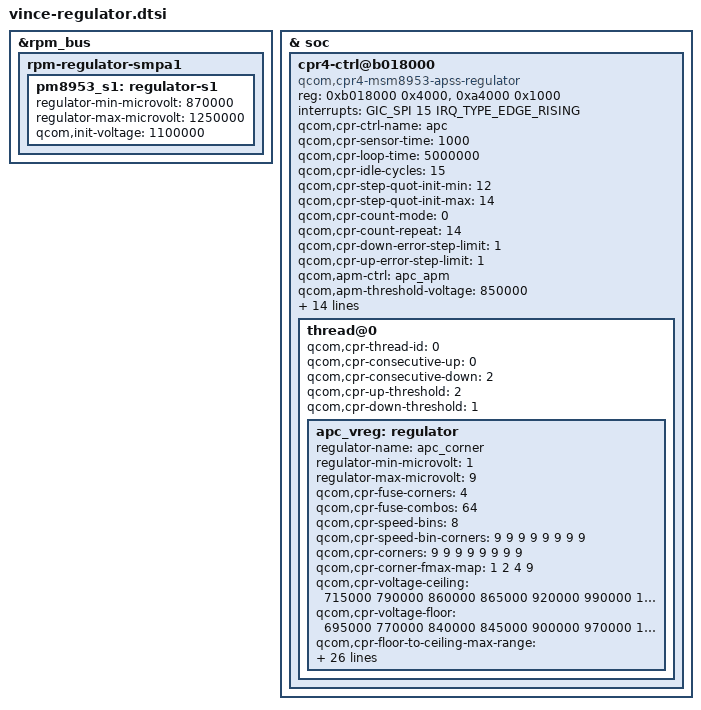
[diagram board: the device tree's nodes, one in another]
/*
 * Copyright (c) 2015-2016, 2019, The Linux Foundation. All rights reserved.
 *
 * This program is free software; you can redistribute it and/or modify
 * it under the terms of the GNU General Public License version 2 and
 * only version 2 as published by the Free Software Foundation.
 *
 * This program is distributed in the hope that it will be useful,
 * but WITHOUT ANY WARRANTY; without even the implied warranty of
 * MERCHANTABILITY or FITNESS FOR A PARTICULAR PURPOSE.  See the
 * GNU General Public License for more details.
 */

&rpm_bus {
	/delete-node/ rpm-regulator-smpa1;

	rpm-regulator-smpa1 {
		status = "okay";
		pm8953_s1: regulator-s1 {
			regulator-min-microvolt =
					<870000>;
			regulator-max-microvolt =
					<1250000>;
			qcom,init-voltage = <1100000>;
			status = "okay";
		};
	};
};

& soc {
	/delete-node/ cpr4-ctrl@b018000;

	cpr4-ctrl@b018000 {
		compatible = "qcom,cpr4-msm8953-apss-regulator";
		reg = <0xb018000 0x4000>, <0xa4000 0x1000>;
		reg-names = "cpr_ctrl", "fuse_base";
		interrupts = <GIC_SPI 15 IRQ_TYPE_EDGE_RISING>;
		interrupt-names = "cpr";

		qcom,cpr-ctrl-name = "apc";

		qcom,cpr-sensor-time = <1000>;
		qcom,cpr-loop-time = <5000000>;
		qcom,cpr-idle-cycles = <15>;
		qcom,cpr-step-quot-init-min = <12>;
		qcom,cpr-step-quot-init-max = <14>;
		qcom,cpr-count-mode = <0>;		/* All-at-once */
		qcom,cpr-count-repeat = <14>;
		qcom,cpr-down-error-step-limit = <1>;
		qcom,cpr-up-error-step-limit = <1>;

		qcom,apm-ctrl = <&apc_apm>;
		qcom,apm-threshold-voltage = <850000>;
		qcom,apm-hysteresis-voltage = <5000>;

		vdd-supply = <&pm8953_s5>;
		qcom,voltage-step = <5000>;
		vdd-limit-supply = <&pm8953_s5_limit>;
		mem-acc-supply = <&apc_mem_acc_vreg>;

		qcom,cpr-enable;
		qcom,cpr-hw-closed-loop;

		qcom,cpr-panic-reg-addr-list =
			<0xb1d2c18 0xb1d2900 0x0b1112b0 0xb018798>;
		qcom,cpr-panic-reg-name-list =
			"CCI_SAW4_PMIC_STS", "CCI_SAW4_VCTL",
			"APCS_ALIAS0_APM_CTLER_STATUS",
			"APCS0_CPR_CORE_ADJ_MODE_REG";

		/* Turbo (corner 6) ceiling voltage */
		qcom,cpr-aging-ref-voltage = <990000>;

		thread@0 {
			qcom,cpr-thread-id = <0>;
			qcom,cpr-consecutive-up = <0>;
			qcom,cpr-consecutive-down = <2>;
			qcom,cpr-up-threshold = <2>;
			qcom,cpr-down-threshold = <1>;

			apc_vreg: regulator {
				regulator-name = "apc_corner";
				regulator-min-microvolt = <1>;
				regulator-max-microvolt = <9>;

				qcom,cpr-fuse-corners = <4>;
				qcom,cpr-fuse-combos = <64>;
				qcom,cpr-speed-bins = <8>;
				qcom,cpr-speed-bin-corners =
					<9 9 9 9 9 9 9 9>;
				qcom,cpr-corners =
					<9 9 9 9 9 9 9 9>;

				qcom,cpr-corner-fmax-map =
					<1 2 4 9>;

				qcom,cpr-voltage-ceiling =
					<715000 790000 860000 865000 920000
					 990000 1065000 1095000 1100000>;

				qcom,cpr-voltage-floor =
					<695000 770000 840000 845000 900000
					 970000 1045000 1075000 1080000>;

				qcom,cpr-floor-to-ceiling-max-range =
					 <50000 50000 50000 50000 50000
					  50000 50000 50000 50000>;

				qcom,mem-acc-voltage =
					<1 1 2 2 2 2 2 2 2>;

				qcom,corner-frequencies =
					<652800000 1036800000 1401600000
					1689600000 1804800000 1958400000
					2016000000 2150400000 2208000000>;

				qcom,cpr-open-loop-voltage-fuse-adjustment =
					<     0      0      0     0>,
					< 25000      0   5000 40000>,
					< 25000      0   5000 40000>,
					< 25000      0   5000 40000>,
					<     0      0      0     0>,
					<     0      0      0     0>,
					<     0      0      0     0>,
					<     0      0      0     0>;

				qcom,cpr-closed-loop-voltage-fuse-adjustment =
					<      0        0        0      0>,
					<  10000 (-15000)        0  25000>,
					<  10000 (-15000)        0  25000>,
					<(-5000) (-30000) (-15000)  10000>,
					<      0        0        0      0>,
					<      0        0        0      0>,
					<      0        0        0      0>,
					<      0        0        0      0>;

				qcom,cpr-ro-scaling-factor =
				      <3610 3790    0 2200 2450 2310 2170 2210
				       2330 2210 2470 2340  780 2700 2450 2090>,
				      <3610 3790    0 2200 2450 2310 2170 2210
				       2330 2210 2470 2340  780 2700 2450 2090>,
				      <3610 3790    0 2200 2450 2310 2170 2210
				       2330 2210 2470 2340  780 2700 2450 2090>,
				      <3610 3790    0 2200 2450 2310 2170 2210
				       2330 2210 2470 2340  780 2700 2450 2090>;

				qcom,allow-voltage-interpolation;
				qcom,allow-quotient-interpolation;
				qcom,cpr-scaled-open-loop-voltage-as-ceiling;

				qcom,cpr-aging-max-voltage-adjustment = <15000>;
				qcom,cpr-aging-ref-corner = <6>; /* Turbo */
				qcom,cpr-aging-ro-scaling-factor = <2800>;
				qcom,allow-aging-voltage-adjustment =
					<0 0 0 1 1 1 1 1>;
			};
		};
	};
};
